# nrf9220_application register map
Vendor: Nordic Semiconductor; Series: nRF92; File version: 1
CPU: CM33 r1p0, little endian, MPU, FPU, 3 interrupt priority bits, 480 interrupts, 4 SAU regions
Registers are 32-bit, read-write, reset 0x0 unless marked. A register's access mark holds for its fields unless they carry their own. Offsets are from the block's base; [hi:lo] are bit positions; lines under a group give offsets from that group; {n}, {i} and the like mark numbered series; 'fields as' and 'values as' point back to an identical list.

## UICR_NS — User information configuration registers
Base 0x0FFF0000
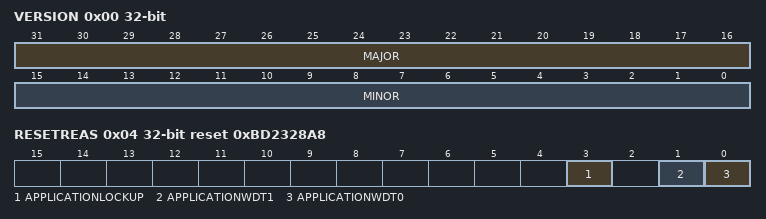
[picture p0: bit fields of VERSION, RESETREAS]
0x00 VERSION — Version of the UICR format
  [31:16] MAJOR — Major version
  [15:0] MINOR — Minor version
0x08 LOCK reset 0xBD2328A8 — Lock the UICR from modification
  [31:0] PALL
    0xBD2328A8=Unlocked (UICR can be written, and is not integrity checked by Nordic IronSide SE); 0xFFFFFFFF=Locked (UICR is read-only, and is integrity checked by Nordic IronSide SE on boot)
0x10 APPROTECT group — Access Port protection settings for debug access control
  0x00 APPLICATION reset 0xBD2328A8 — APPLICATION access port protection
    [31:0] PALL
      0xBD2328A8=Unprotected (Full debug access enabled through the access port); 0x1730C77F=Profile1 (Reserved for future use); 0xF05F1363=Profile2 (Reserved for future use); 0x488C5ED6=Profile3 (Reserved for future use); 0x83C6B58D=Profile4 (Reserved for future use); 0xFFFFFFFF=Protected (Debug access fully disabled through the access port)
  0x0C CORESIGHT reset 0xBD2328A8 — CoreSight access port protection
    fields as APPROTECT.APPLICATION
0x20 ERASEPROTECT reset 0xBD2328A8 — Erase protection
  [31:0] PALL
    0xBD2328A8=Unprotected (ERASEALL operation is allowed); 0xFFFFFFFF=Protected (ERASEALL operation is blocked)
0x24 PROTECTEDMEM group — Protected Memory region configuration for integrity-checked immutable bootloaders and data
  0x00 ENABLE reset 0xBD2328A8 — Enable the Protected Memory region
    [31:0] ENABLE
      0xBD2328A8=Disabled (Protected Memory region is disabled, no integrity checking); 0xFFFFFFFF=Enabled (Protected Memory region is enabled and integrity checked by IronSide SE)
  0x04 SIZE4KB reset 0xBD2328A8 — Protected Memory region size in 4 kiB blocks.
0x2C WDTSTART group — Start a local watchdog timer ahead of the CPU boot.
  0x00 ENABLE reset 0xBD2328A8 — Enable watchdog timer start.
    [31:0] ENABLE
      0xBD2328A8=Disabled (Watchdog timer is not started automatically); 0xFFFFFFFF=Enabled (Watchdog timer is started automatically ahead of CPU boot)
  0x04 INSTANCE reset 0xBD2328A8 — Watchdog timer instance.
    [31:0] INSTANCE
      0xBD2328A8=WDT0 (Use WDT0 instance); 0x1730C77F=WDT1 (Use WDT1 instance)
  0x08 CRV reset 0xBD2328A8 — Initial CRV (Counter Reload Value) register value.
    [31:0] CRV — Initial CRV value for the WDT
0x3C SECURESTORAGE group — Secure Storage configuration
  0x00 ENABLE reset 0xBD2328A8 — Enable the Secure Storage
    [31:0] ENABLE
      0xBD2328A8=Disabled (Secure Storage is disabled); 0xFFFFFFFF=Enabled (Secure Storage is enabled and configured)
  0x04 ADDRESS reset 0xBD2328A8 — Start address of the Secure Storage region
  0x08 CRYPTO group — Secure Storage partitions for the Cryptographic service
    0x00 APPLICATIONSIZE1KB reset 0xBD2328A8 — Size of the APPLICATION partition in 1 kiB blocks
      [31:0] SIZE1KB
  0x10 ITS group — Secure Storage partitions for the Internal Trusted Storage service
    0x00 APPLICATIONSIZE1KB reset 0xBD2328A8 — Size of the APPLICATION partition in 1 kiB blocks
      [31:0] SIZE1KB
0x68 PERIPHCONF group — Global domain peripheral configuration
  0x00 ENABLE reset 0xBD2328A8 — Enable the global domain peripheral configuration
    [31:0] ENABLE
      0xBD2328A8=Disabled (Global domain peripheral configuration is disabled); 0xFFFFFFFF=Enabled (Global domain peripheral configuration is enabled and will be applied)
  0x04 ADDRESS reset 0xBD2328A8 — Start address of the array of peripheral configuration entries
  0x08 MAXCOUNT reset 0xBD2328A8 — Maximum number of peripheral configuration entries
0x74 MPCCONF group — Global domain MPC configuration
  0x00 ENABLE reset 0xBD2328A8 — Enable the global domain MPC configuration
    [31:0] ENABLE
      0xBD2328A8=Disabled (Global domain MPC configuration is disabled); 0xFFFFFFFF=Enabled (Global domain MPC configuration is enabled and will be applied)
  0x04 ADDRESS reset 0xBD2328A8 — Start address of the array of MPC configuration entries
  0x08 MAXCOUNT reset 0xBD2328A8 — Maximum number of MPC configuration entries
0x80 SECONDARY group — Secondary firmware configuration
  0x00 ENABLE reset 0xBD2328A8 — Enable booting of secondary firmware.
    [31:0] ENABLE
      0xBD2328A8=Disabled (Secondary firmware boot is disabled); 0xFFFFFFFF=Enabled (Secondary firmware boot is enabled)
  0x04 PROCESSOR reset 0xBD2328A8 — Processor to boot for the secondary firmware.
    [31:0] PROCESSOR
      0xBD2328A8=APPLICATION (Boot the APPLICATION processor.)
  0x08 TRIGGER group — Automatic triggers for reset into secondary firmware
    0x00 ENABLE reset 0xBD2328A8 — Enable automatic triggers for reset into secondary firmware
      [31:0] ENABLE
        0xBD2328A8=Disabled (Automatic triggers for secondary firmware are disabled); 0xFFFFFFFF=Enabled (Automatic triggers for secondary firmware are enabled)
    0x04 RESETREAS reset 0xBD2328A8 — Reset reasons that trigger automatic reset into secondary firmware
      [all] fields
        1=Enabled (This reset reason will trigger secondary firmware boot); 0=Disabled (This reset reason will not trigger secondary firmware boot)
      [3] APPLICATIONLOCKUP
      [1] APPLICATIONWDT1
      [0] APPLICATIONWDT0
  0x14 ADDRESS reset 0xBD2328A8 — Start address of the secondary firmware. This value is used as the initial value of the secure VTOR (Vector Table Offset Register) after CPU reset.
    [31:12] ADDRESS
  0x18 PROTECTEDMEM group — Protected Memory region for the secondary firmware.
    0x00 ENABLE reset 0xBD2328A8 — Enable Protected Memory region for the secondary firmware. The region starts at ADDRESS.
      [31:0] ENABLE
        0xBD2328A8=Disabled (Protected Memory region for secondary firmware is disabled); 0xFFFFFFFF=Enabled (Protected Memory region for secondary firmware is enabled and integrity checked)
    0x04 SIZE4KB reset 0xBD2328A8 — Protected Memory region size for the secondary firmware.
  0x20 WDTSTART group — Start a local watchdog timer ahead of the CPU boot.
    0x00 ENABLE reset 0xBD2328A8 — Enable watchdog timer start.
      [31:0] ENABLE
        0xBD2328A8=Disabled (Watchdog timer for secondary firmware is not started automatically); 0xFFFFFFFF=Enabled (Watchdog timer for secondary firmware is started automatically ahead of CPU boot)
    0x04 INSTANCE reset 0xBD2328A8 — Watchdog timer instance.
      [31:0] INSTANCE
        0xBD2328A8=WDT0 (Use WDT0 instance for secondary firmware); 0x1730C77F=WDT1 (Use WDT1 instance for secondary firmware)
    0x08 CRV reset 0xBD2328A8 — Initial CRV (Counter Reload Value) register value.
      [31:0] CRV — Initial CRV value for the WDT
  0x2C PERIPHCONF group — Global domain peripheral configuration used when booting the secondary firmware.
    0x00 ENABLE reset 0xBD2328A8 — Enable global domain peripheral configuration for the secondary firmware.
      [31:0] ENABLE
        0xBD2328A8=Disabled (Peripheral configuration for secondary firmware is disabled); 0xFFFFFFFF=Enabled (Peripheral configuration for secondary firmware is enabled and will be applied)
    0x04 ADDRESS reset 0xBD2328A8 — Start address of the array of peripheral configuration entries for the secondary firmware.
    0x08 MAXCOUNT reset 0xBD2328A8 — Maximum number of peripheral configuration entries for the secondary firmware.
  0x38 MPCCONF group — Global domain MPC configuration used when booting the secondary firmware
    0x00 ENABLE reset 0xBD2328A8 — Enable the global domain MPC configuration for the secondary firmware
      [31:0] ENABLE
        0xBD2328A8=Disabled (MPC configuration for secondary firmware is disabled); 0xFFFFFFFF=Enabled (MPC configuration for secondary firmware is enabled and will be applied)
    0x04 ADDRESS reset 0xBD2328A8 — Start address of the array of MPC configuration entries for the secondary firmware
    0x08 MAXCOUNT reset 0xBD2328A8 — Maximum number of MPC configuration entries for the secondary firmware
{0xC4+4i} PADDING[{i}] (i=0..15) reset 0xBD2328A8 — Description collection: Abstract collection

## Notices in the file
Copyright (c) 2010 - 2026, Nordic Semiconductor ASA All rights reserved.
SPDX-License-Identifier: BSD-3-Clause
Redistribution and use in source and binary forms, with or without
modification, are permitted provided that the following conditions are met:
1. Redistributions of source code must retain the above copyright notice, this
list of conditions and the following disclaimer.
2. Redistributions in binary form must reproduce the above copyright
notice, this list of conditions and the following disclaimer in the
documentation and/or other materials provided with the distribution.
3. Neither the name of Nordic Semiconductor ASA nor the names of its
contributors may be used to endorse or promote products derived from this
software without specific prior written permission.
THIS SOFTWARE IS PROVIDED BY THE COPYRIGHT HOLDERS AND CONTRIBUTORS "AS IS"
AND ANY EXPRESS OR IMPLIED WARRANTIES, INCLUDING, BUT NOT LIMITED TO, THE
IMPLIED WARRANTIES OF MERCHANTABILITY, AND FITNESS FOR A PARTICULAR PURPOSE
ARE DISCLAIMED. IN NO EVENT SHALL NORDIC SEMICONDUCTOR ASA OR CONTRIBUTORS BE
LIABLE FOR ANY DIRECT, INDIRECT, INCIDENTAL, SPECIAL, EXEMPLARY, OR
CONSEQUENTIAL DAMAGES (INCLUDING, BUT NOT LIMITED TO, PROCUREMENT OF
SUBSTITUTE GOODS OR SERVICES; LOSS OF USE, DATA, OR PROFITS; OR BUSINESS
INTERRUPTION) HOWEVER CAUSED AND ON ANY THEORY OF LIABILITY, WHETHER IN
CONTRACT, STRICT LIABILITY, OR TORT (INCLUDING NEGLIGENCE OR OTHERWISE)
ARISING IN ANY WAY OUT OF THE USE OF THIS SOFTWARE, EVEN IF ADVISED OF THE
POSSIBILITY OF SUCH DAMAGE.
